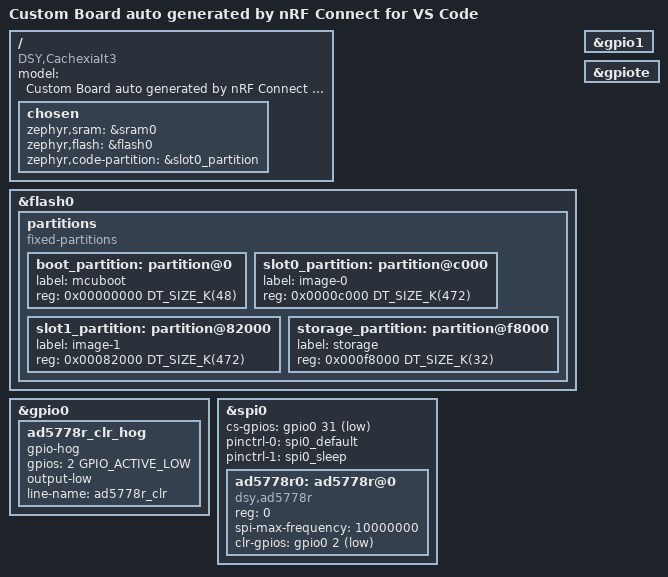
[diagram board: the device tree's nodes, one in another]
/dts-v1/;
#include <nordic/nrf52840_qfaa.dtsi>
#include "CachexiaIt3-pinctrl.dtsi"

/ {
	model = "Custom Board auto generated by nRF Connect for VS Code";
	compatible = "DSY,CachexiaIt3";

	chosen {
		zephyr,sram = &sram0;
		zephyr,flash = &flash0;
		zephyr,code-partition = &slot0_partition;
	};
};

&flash0 {
	partitions {
		compatible = "fixed-partitions";
		#address-cells = <1>;
		#size-cells = <1>;

		boot_partition: partition@0 {
			label = "mcuboot";
			reg = <0x00000000 DT_SIZE_K(48)>;
		};

		slot0_partition: partition@c000 {
			label = "image-0";
			reg = <0x0000c000 DT_SIZE_K(472)>;
		};

		slot1_partition: partition@82000 {
			label = "image-1";
			reg = <0x00082000 DT_SIZE_K(472)>;
		};

		storage_partition: partition@f8000 {
			label = "storage";
			reg = <0x000f8000 DT_SIZE_K(32)>;
		};
	};
};

&gpio0 {
    status = "okay";

    ad5778r_clr_hog: ad5778r_clr_hog {
        gpio-hog;
        gpios = <2 GPIO_ACTIVE_LOW>;
        output-low;          /* 对 active-low 的 CLR 来说：high = inactive */
        line-name = "ad5778r_clr";
    };
};

&gpio1 { status = "okay"; };

&gpiote {
    status = "okay";
};

&spi0 {
	status = "okay";
	pinctrl-names = "default", "sleep";
	cs-gpios = <&gpio0 31 GPIO_ACTIVE_LOW>;
	pinctrl-0 = <&spi0_default>;
	pinctrl-1 = <&spi0_sleep>;
	ad5778r0: ad5778r@0 {
		compatible = "dsy,ad5778r";
		reg = <0>;
		spi-max-frequency = <10000000>;

		/* 建议按 datasheet：LDAC/CLR 都是 active-low（不用就绑 IOVCC） */
		// ldac-gpios = <&gpio0 10 GPIO_ACTIVE_LOW>;
		clr-gpios  = <&gpio0 2 GPIO_ACTIVE_LOW>;

		/* 如果你要用 toggle select/global toggle 的“软件切换”，TGP 需要为高 */
		/* tgp-gpios = <&gpio0 12 GPIO_ACTIVE_HIGH>; */
		/* tgp-default-high; */

		/* 如果 SDO 接了 MCU 并且上拉了，可以开 readback */
		/* sdo-readback; */

		/* 可选：用外部参考（硬件上 REFCOMP 必须接地） */
		/* external-reference; */
	};
};

